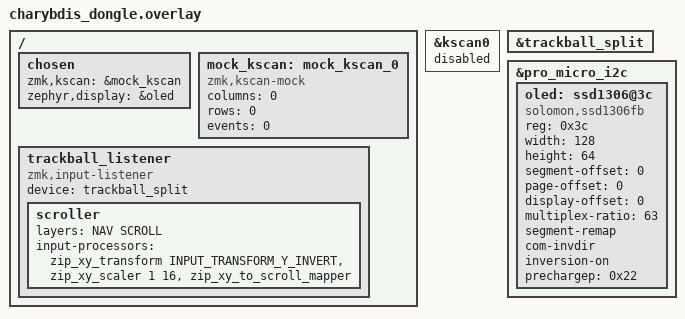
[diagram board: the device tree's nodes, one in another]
/*
 * Copyright (c) 2024 The ZMK Contributors
 *
 * SPDX-License-Identifier: MIT
 */

#include "charybdis.dtsi"
#include <zephyr/dt-bindings/input/input-event-codes.h>
#include <input/processors.dtsi>
#include <dt-bindings/zmk/input_transform.h>

#define NAV     2
#define SCROLL  5

/ {
    chosen {
        zmk,kscan = &mock_kscan;
        zephyr,display = &oled;
    };

    mock_kscan: mock_kscan_0 {
        compatible = "zmk,kscan-mock";
        columns = <0>;
        rows = <0>;
        events = <0>;
    };

    trackball_listener {
        compatible = "zmk,input-listener";
        device = <&trackball_split>;

        scroller {
            layers = <NAV SCROLL>;
            input-processors = <&zip_xy_transform INPUT_TRANSFORM_Y_INVERT>,
                               <&zip_xy_scaler 1 16>,
                               <&zip_xy_to_scroll_mapper>;
        };
    };
};

&kscan0 {
    status = "disabled";
};

&trackball_split {
    status = "okay";
};

&pro_micro_i2c {
    status = "okay";

    oled: ssd1306@3c {
        compatible = "solomon,ssd1306fb";
        reg = <0x3c>;
        width = <128>;
        height = <64>;
        segment-offset = <0>;
        page-offset = <0>;
        display-offset = <0>;
        multiplex-ratio = <63>;
        segment-remap;
        com-invdir;
        inversion-on;
        prechargep = <0x22>;
    };
};

